VERSION ""

NS_ :

BS_:

BU_: CLUSTER INVERTER

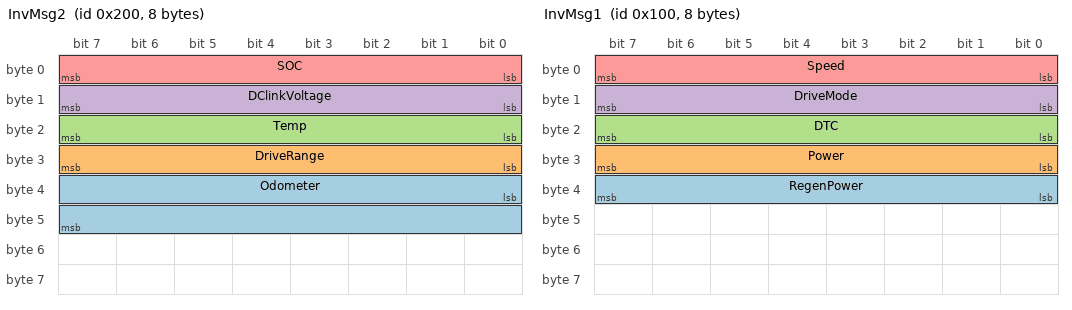
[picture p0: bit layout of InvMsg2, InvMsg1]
BO_ 512 InvMsg2: 8 INVERTER
 SG_ Odometer : 32|16@1+ (5,0) [0|327675] "km"  CLUSTER
 SG_ DriveRange : 24|8@1+ (1,0) [0|255] "km"  CLUSTER
 SG_ Temp : 16|8@1+ (1,-20) [-20|235] "degC"  CLUSTER
 SG_ DClinkVoltage : 8|8@1+ (1,0) [0|80] "V"  CLUSTER
 SG_ SOC : 0|8@1+ (1,0) [0|100] "%"  CLUSTER

BO_ 256 InvMsg1: 8 INVERTER
 SG_ RegenPower : 32|8@1+ (1,0) [0|255] "kW"  CLUSTER
 SG_ Power : 24|8@1+ (1,0) [0|255] "kW"  CLUSTER
 SG_ DTC : 16|8@1+ (1,0) [0|255] ""  CLUSTER
 SG_ DriveMode : 8|8@1+ (1,0) [0|3] ""  CLUSTER
 SG_ Speed : 0|8@1+ (1,-10) [-10|245] "km/h"  CLUSTER

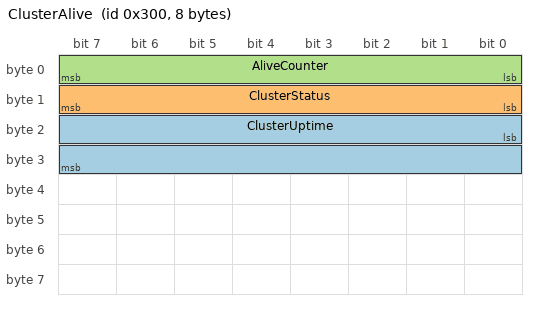
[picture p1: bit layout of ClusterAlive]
BO_ 768 ClusterAlive: 8 CLUSTER
 SG_ ClusterUptime : 16|16@1+ (1,0) [0|65535] "s"  INVERTER
 SG_ ClusterStatus : 8|8@1+ (1,0) [0|255] ""  INVERTER
 SG_ AliveCounter : 0|8@1+ (1,0) [0|255] ""  INVERTER

EV_ EnvKlemme30: 0 [0|1] "" 1 1 DUMMY_NODE_VECTOR0 Vector__XXX;

EV_ EnvKlemme15: 0 [0|1] "" 0 2 DUMMY_NODE_VECTOR0 Vector__XXX;

CM_ BO_ 768 "CLUSTER to INVERTER alive message, added 2026-08-07. See docs/design/can-signals.md for details.";
CM_ SG_ 768 AliveCounter "Rolls over 0-255. Incremented when the frame is accepted by the TX buffer, NOT on bus ACK.";
CM_ SG_ 768 ClusterStatus "Bit mask, NOT an enum: bit0=InvMsg1 rx ok, bit1=InvMsg2 rx ok, bit2=BLE app connected, bit3=DTC active, bit4=UI render task alive.";
CM_ SG_ 768 ClusterUptime "Seconds since boot, saturates at 65535 instead of wrapping.";
BA_DEF_ BU_  "NodeLayerModules" STRING ;
BA_DEF_ BO_  "GenMsgILSupport" ENUM  "No","Yes";
BA_DEF_  "NmBaseAddress" HEX 1024 1087;
BA_DEF_  "BusType" STRING ;
BA_DEF_ BO_  "GenMsgCycleTime" INT 0 50000;
BA_DEF_ BO_  "GenMsgSendType" ENUM  "Cyclic","NotUsed","NotUsed","NotUsed","NotUsed","NotUsed","NotUsed","IfActive","NoMsgSendType","NotUsed","vector_leerstring";
BA_DEF_ SG_  "GenSigSendType" ENUM  "Cyclic","OnWrite","OnWriteWithRepetition","OnChange","OnChangeWithRepetition","IfActive","IfActiveWithRepetition","NoSigSendType","NotUsed","NotUsed","NotUsed","NotUsed","NotUsed";
BA_DEF_ SG_  "GenSigStartValue" FLOAT 0 100000000000;
BA_DEF_DEF_  "NodeLayerModules" "CANoeILNLVector.dll";
BA_DEF_DEF_  "GenMsgILSupport" "Yes";
BA_DEF_DEF_  "NmBaseAddress" 1024;
BA_DEF_DEF_  "BusType" "";
BA_DEF_DEF_  "GenMsgCycleTime" 0;
BA_DEF_DEF_  "GenMsgSendType" "NoMsgSendType";
BA_DEF_DEF_  "GenSigSendType" "Cyclic";
BA_DEF_DEF_  "GenSigStartValue" 0;
BA_ "BusType" "CAN";
BA_ "GenMsgCycleTime" BO_ 512 200;
BA_ "GenMsgCycleTime" BO_ 256 100;
BA_ "GenMsgCycleTime" BO_ 768 500;
BA_ "GenSigStartValue" SG_ 512 Temp 20;
BA_ "GenSigStartValue" SG_ 256 Speed 10;
VAL_ 256 DriveMode 0 "P" 1 "R" 2 "N" 3 "D" ;
